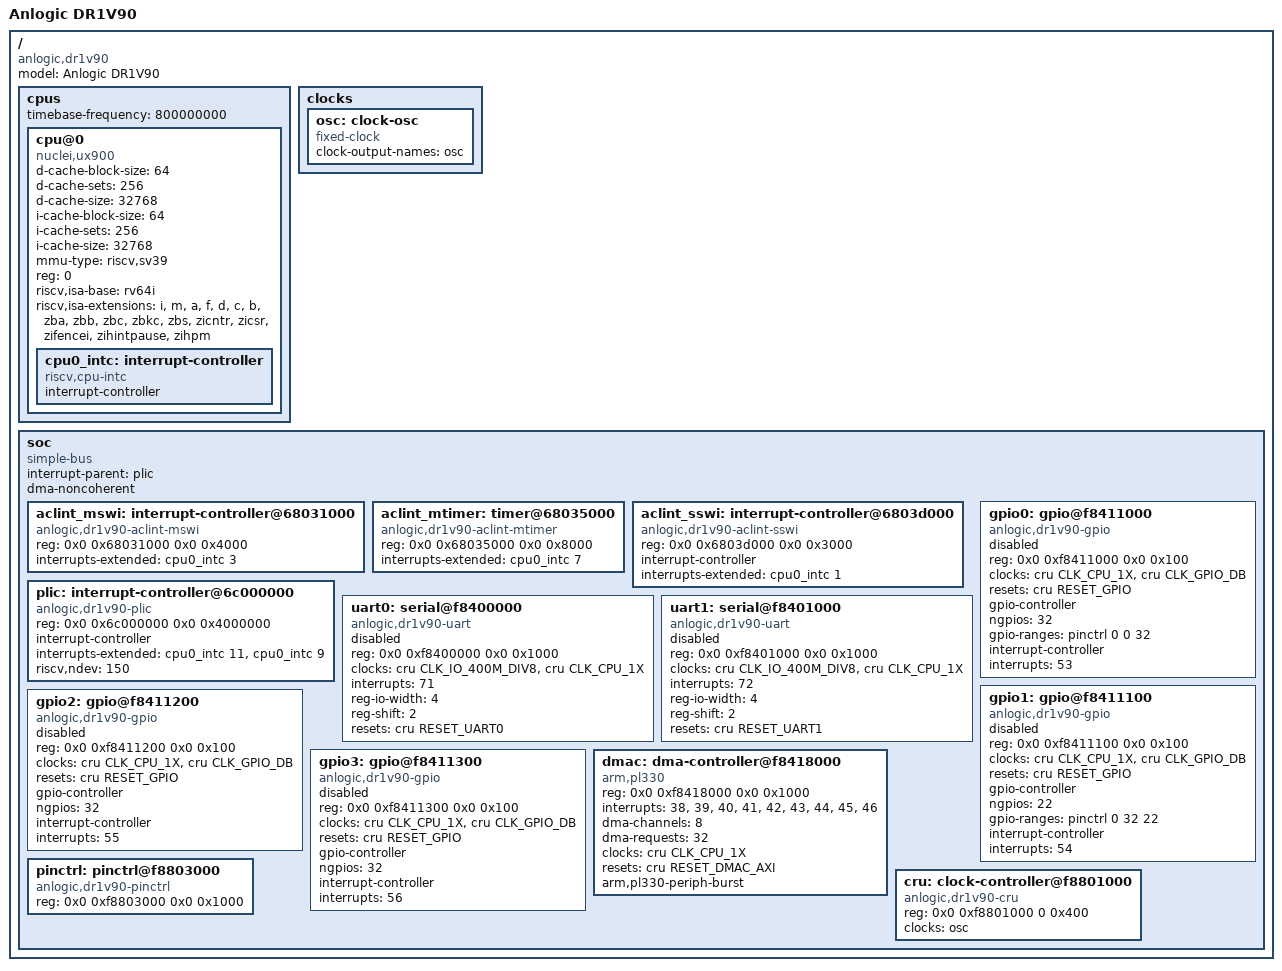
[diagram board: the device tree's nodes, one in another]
// SPDX-License-Identifier: GPL-2.0 OR MIT
/*
 * Copyright (C) 2025 Junhui Liu <junhui.liu@pigmoral.tech>
 */

#include <dt-bindings/clock/anlogic,dr1v90-cru.h>
#include <dt-bindings/reset/anlogic,dr1v90-cru.h>

/dts-v1/;
/ {
	#address-cells = <2>;
	#size-cells = <2>;
	model = "Anlogic DR1V90";
	compatible = "anlogic,dr1v90";

	cpus {
		#address-cells = <1>;
		#size-cells = <0>;
		timebase-frequency = <800000000>;

		cpu@0 {
			compatible = "nuclei,ux900", "riscv";
			d-cache-block-size = <64>;
			d-cache-sets = <256>;
			d-cache-size = <32768>;
			device_type = "cpu";
			i-cache-block-size = <64>;
			i-cache-sets = <256>;
			i-cache-size = <32768>;
			mmu-type = "riscv,sv39";
			reg = <0>;
			riscv,isa-base = "rv64i";
			riscv,isa-extensions = "i", "m", "a", "f", "d", "c", "b",
					       "zba", "zbb", "zbc", "zbkc", "zbs",
					       "zicntr", "zicsr", "zifencei",
					       "zihintpause", "zihpm";

			cpu0_intc: interrupt-controller {
				compatible = "riscv,cpu-intc";
				#interrupt-cells = <1>;
				interrupt-controller;
			};
		};
	};

	clocks {
		osc: clock-osc {
			compatible = "fixed-clock";
			clock-output-names = "osc";
			#clock-cells = <0>;
		};
	};

	soc {
		compatible = "simple-bus";
		interrupt-parent = <&plic>;
		#address-cells = <2>;
		#size-cells = <2>;
		ranges;
		dma-noncoherent;

		aclint_mswi: interrupt-controller@68031000 {
			compatible = "anlogic,dr1v90-aclint-mswi", "nuclei,ux900-aclint-mswi";
			reg = <0x0 0x68031000 0x0 0x4000>;
			interrupts-extended = <&cpu0_intc 3>;
		};

		aclint_mtimer: timer@68035000 {
			compatible = "anlogic,dr1v90-aclint-mtimer", "nuclei,ux900-aclint-mtimer";
			reg = <0x0 0x68035000 0x0 0x8000>;
			reg-names = "mtimecmp";
			interrupts-extended = <&cpu0_intc 7>;
		};

		aclint_sswi: interrupt-controller@6803d000 {
			compatible = "anlogic,dr1v90-aclint-sswi", "nuclei,ux900-aclint-sswi";
			reg = <0x0 0x6803d000 0x0 0x3000>;
			#interrupt-cells = <0>;
			interrupt-controller;
			interrupts-extended = <&cpu0_intc 1>;
		};

		plic: interrupt-controller@6c000000 {
			compatible = "anlogic,dr1v90-plic", "sifive,plic-1.0.0";
			reg = <0x0 0x6c000000 0x0 0x4000000>;
			#address-cells = <0>;
			#interrupt-cells = <1>;
			interrupt-controller;
			interrupts-extended = <&cpu0_intc 11>, <&cpu0_intc 9>;
			riscv,ndev = <150>;
		};

		uart0: serial@f8400000 {
			compatible = "anlogic,dr1v90-uart", "snps,dw-apb-uart";
			reg = <0x0 0xf8400000 0x0 0x1000>;
			clocks = <&cru CLK_IO_400M_DIV8>, <&cru CLK_CPU_1X>;
			clock-names = "baudclk", "apb_pclk";
			interrupts = <71>;
			reg-io-width = <4>;
			reg-shift = <2>;
			resets = <&cru RESET_UART0>;
			status = "disabled";
		};

		uart1: serial@f8401000 {
			compatible = "anlogic,dr1v90-uart", "snps,dw-apb-uart";
			reg = <0x0 0xf8401000 0x0 0x1000>;
			clocks = <&cru CLK_IO_400M_DIV8>, <&cru CLK_CPU_1X>;
			clock-names = "baudclk", "apb_pclk";
			interrupts = <72>;
			reg-io-width = <4>;
			reg-shift = <2>;
			resets = <&cru RESET_UART1>;
			status = "disabled";
		};

		gpio0: gpio@f8411000 {
			compatible = "anlogic,dr1v90-gpio";
			reg = <0x0 0xf8411000 0x0 0x100>;
			clocks = <&cru CLK_CPU_1X>, <&cru CLK_GPIO_DB>;
			clock-names = "bus", "db";
			resets = <&cru RESET_GPIO>;
			gpio-controller;
			#gpio-cells = <2>;
			ngpios = <32>;
			gpio-ranges = <&pinctrl 0 0 32>;
			interrupt-controller;
			#interrupt-cells = <2>;
			interrupts = <53>;
			status = "disabled";
		};

		gpio1: gpio@f8411100 {
			compatible = "anlogic,dr1v90-gpio";
			reg = <0x0 0xf8411100 0x0 0x100>;
			clocks = <&cru CLK_CPU_1X>, <&cru CLK_GPIO_DB>;
			clock-names = "bus", "db";
			resets = <&cru RESET_GPIO>;
			gpio-controller;
			#gpio-cells = <2>;
			ngpios = <22>;
			gpio-ranges = <&pinctrl 0 32 22>;
			interrupt-controller;
			#interrupt-cells = <2>;
			interrupts = <54>;
			status = "disabled";
		};

		gpio2: gpio@f8411200 {
			compatible = "anlogic,dr1v90-gpio";
			reg = <0x0 0xf8411200 0x0 0x100>;
			clocks = <&cru CLK_CPU_1X>, <&cru CLK_GPIO_DB>;
			clock-names = "bus", "db";
			resets = <&cru RESET_GPIO>;
			gpio-controller;
			#gpio-cells = <2>;
			ngpios = <32>;
			interrupt-controller;
			#interrupt-cells = <2>;
			interrupts = <55>;
			status = "disabled";
		};

		gpio3: gpio@f8411300 {
			compatible = "anlogic,dr1v90-gpio";
			reg = <0x0 0xf8411300 0x0 0x100>;
			clocks = <&cru CLK_CPU_1X>, <&cru CLK_GPIO_DB>;
			clock-names = "bus", "db";
			resets = <&cru RESET_GPIO>;
			gpio-controller;
			#gpio-cells = <2>;
			ngpios = <32>;
			interrupt-controller;
			#interrupt-cells = <2>;
			interrupts = <56>;
			status = "disabled";
		};

		dmac: dma-controller@f8418000 {
			compatible = "arm,pl330", "arm,primecell";
			reg = <0x0 0xf8418000 0x0 0x1000>;
			interrupts = <38>, <39>, <40>, <41>, <42>, <43>, <44>, <45>, <46>;
			#dma-cells = <1>;
			dma-channels = <8>;
			dma-requests = <32>;
			clocks = <&cru CLK_CPU_1X>;
			clock-names = "apb_pclk";
			resets = <&cru RESET_DMAC_AXI>;
			reset-names = "dma-ocp";
			arm,pl330-periph-burst;
		};

		pinctrl: pinctrl@f8803000 {
			compatible = "anlogic,dr1v90-pinctrl";
			reg = <0x0 0xf8803000 0x0 0x1000>;
		};

		cru: clock-controller@f8801000 {
			compatible = "anlogic,dr1v90-cru";
			reg = <0x0 0xf8801000 0 0x400>;
			clocks = <&osc>;
			clock-names = "osc";
			#clock-cells = <1>;
			#reset-cells = <1>;
		};
	};
};
